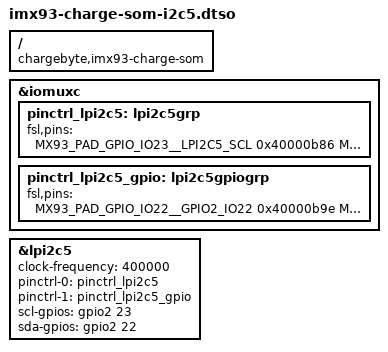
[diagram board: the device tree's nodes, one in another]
// SPDX-License-Identifier: GPL-2.0
/*
 * Copyright (C) 2026 chargebyte GmbH
 * Author: Michael Heimpold <michael.heimpold@chargebyte.com>
 */

#include <dt-bindings/gpio/gpio.h>
#include "imx93-pinfunc.h"

/dts-v1/;
/plugin/;

/ {
	compatible = "chargebyte,imx93-charge-som";
};

&iomuxc {
	pinctrl_lpi2c5: lpi2c5grp {
		/* sion, drive strength: X2, slew rate: fast, pull up, open drain */
		fsl,pins = <
			MX93_PAD_GPIO_IO23__LPI2C5_SCL		0x40000b86
			MX93_PAD_GPIO_IO22__LPI2C5_SDA		0x40000b86
		>;
	};

	pinctrl_lpi2c5_gpio: lpi2c5gpiogrp {
		fsl,pins = <
			MX93_PAD_GPIO_IO22__GPIO2_IO22		0x40000b9e
			MX93_PAD_GPIO_IO23__GPIO2_IO23		0x40000b9e
		>;
	};
};

&lpi2c5 {
	clock-frequency = <400000>;
	pinctrl-names = "default", "gpio";
	pinctrl-0 = <&pinctrl_lpi2c5>;
	pinctrl-1 = <&pinctrl_lpi2c5_gpio>;
	scl-gpios = <&gpio2 23 (GPIO_ACTIVE_HIGH | GPIO_OPEN_DRAIN)>;
	sda-gpios = <&gpio2 22 (GPIO_ACTIVE_HIGH | GPIO_OPEN_DRAIN)>;
	#address-cells = <1>;
	#size-cells = <0>;
	status = "okay";
};
